VERSION ""

NS_ :

BS_:

BU_: STM32Discovery

BO_ 2566852658 BMP085: 8 STM32Discovery
 SG_ BMP085_Temperature : 32|32@1+ (0.1,0) [0|0] ""  STM32Discovery
 SG_ BMP085_Pressure : 0|32@1- (1,0) [0|0] ""  STM32Discovery

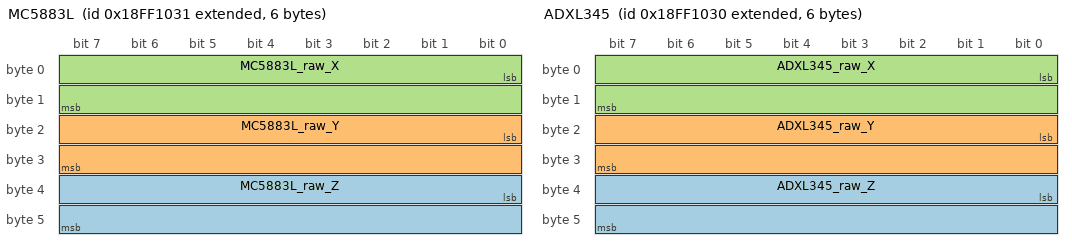
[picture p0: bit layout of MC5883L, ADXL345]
BO_ 2566852657 MC5883L: 6 STM32Discovery
 SG_ MC5883L_raw_Z : 32|16@1- (1,0) [0|0] ""  STM32Discovery
 SG_ MC5883L_raw_Y : 16|16@1- (1,0) [0|0] ""  STM32Discovery
 SG_ MC5883L_raw_X : 0|16@1- (1,0) [0|0] ""  STM32Discovery

BO_ 2566852656 ADXL345: 6 STM32Discovery
 SG_ ADXL345_raw_Z : 32|16@1- (1,0) [0|0] ""  STM32Discovery
 SG_ ADXL345_raw_Y : 16|16@1- (1,0) [0|0] ""  STM32Discovery
 SG_ ADXL345_raw_X : 0|16@1- (1,0) [0|0] ""  STM32Discovery

CM_ BO_ 2566852658 "BMP085 Barometric Pressure Sensor TX MSG";
CM_ BO_ 2566852657 "MC5883L 3-Axis Digital Compass TX MSG";
CM_ BO_ 2566852656 "ADXL345 Accelerometer TX MSG";
BA_DEF_  "BusType" STRING ;
BA_DEF_DEF_  "BusType" "CAN";
